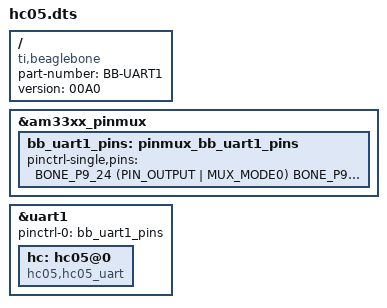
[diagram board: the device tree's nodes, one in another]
/*
 * Copyright (C) 2013 CircuitCo
 *
 * Virtual cape for UART1 on connector pins P9.24 P9.26
 *
 * This program is free software; you can redistribute it and/or modify
 * it under the terms of the GNU General Public License version 2 as
 * published by the Free Software Foundation.
 */

/dts-v1/;
/plugin/;


/ {
	compatible = "ti,beaglebone", "ti,beaglebone-black", "ti,beaglebone-green";

	part-number = "BB-UART1";
	version = "00A0";


	/*
	 * Free up the pins used by the cape from the pinmux helpers.
	 */


	fragment@1 {
		target = <&am33xx_pinmux>;
		__overlay__ {
			bb_uart1_pins: pinmux_bb_uart1_pins {
				pinctrl-single,pins = <
					BONE_P9_24 (PIN_OUTPUT | MUX_MODE0)	// uart1_txd.uart1_txd
					BONE_P9_26 (PIN_INPUT | MUX_MODE0)	// uart1_rxd.uart1_rxd
				>;
			};
		};
	};

	fragment@2 {
		target = <&uart1>;

		__overlay__ {
			status = "okay";
			pinctrl-names = "default";
			pinctrl-0 = <&bb_uart1_pins>;

               hc: hc05@0 {
                 compatible = "hc05,hc05_uart";
                 status = "okay";
               };

		};
	};
};
